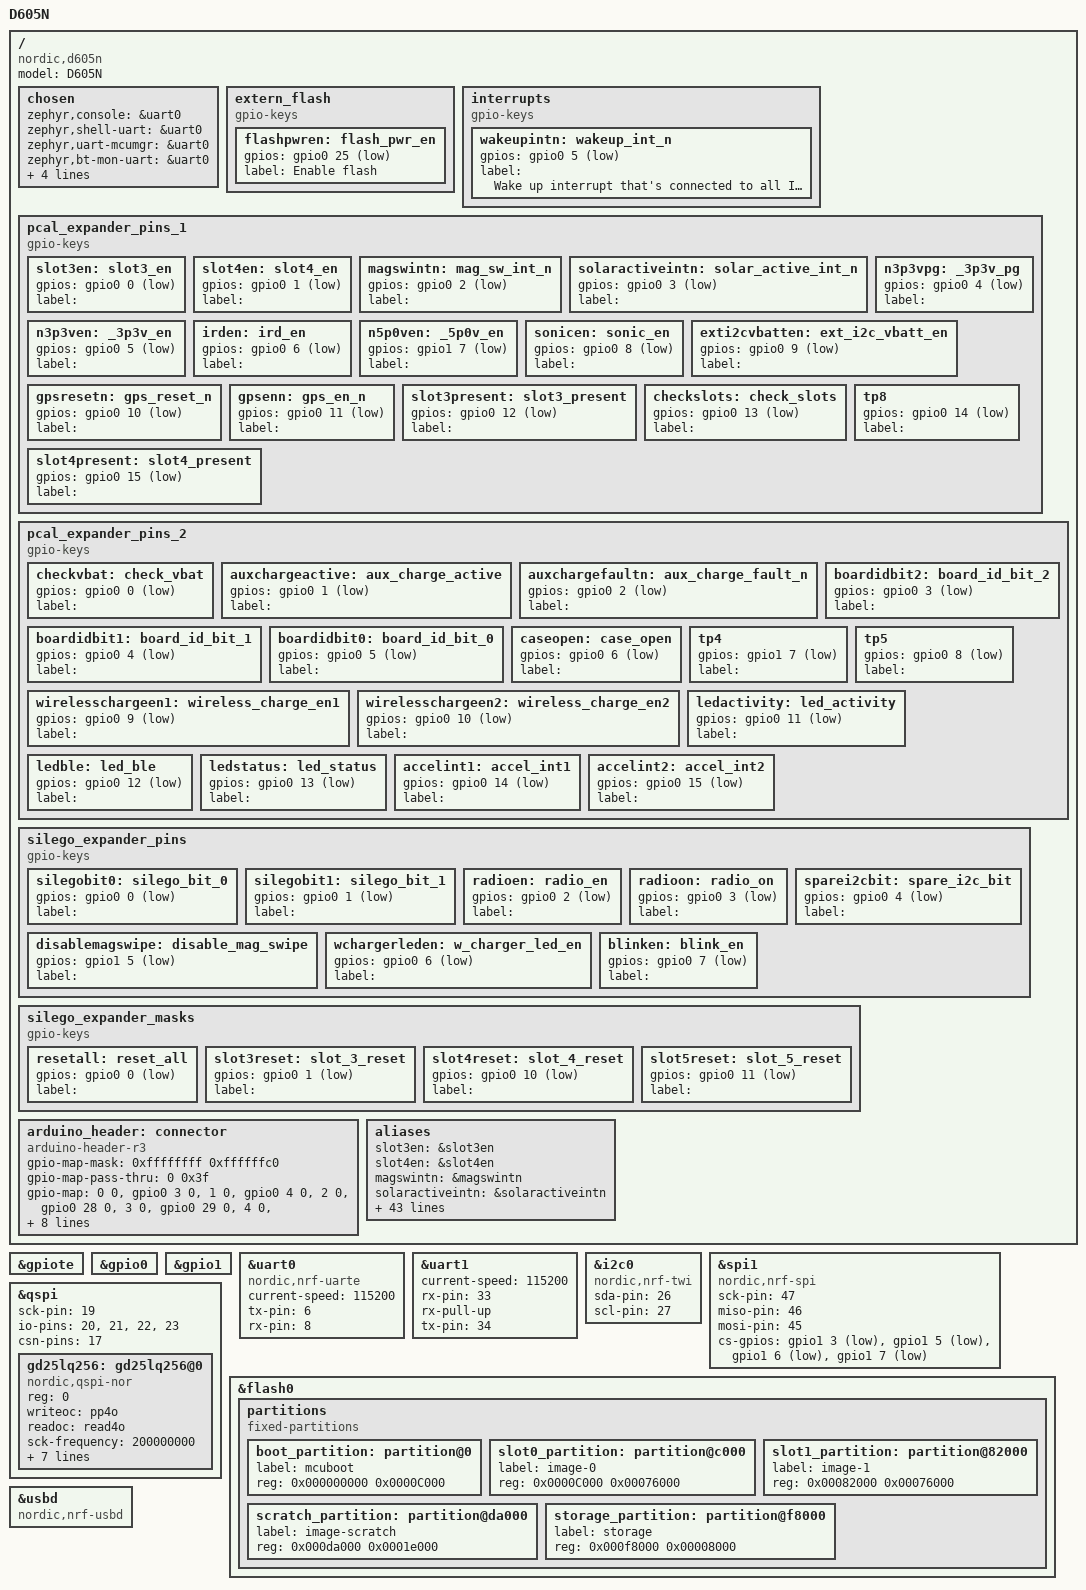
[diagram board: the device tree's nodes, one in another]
/*
 * Copyright (c) 2017 Linaro Limited
 *
 * SPDX-License-Identifier: Apache-2.0
 */

/dts-v1/;
#include <nordic/nrf52840_qiaa.dtsi>

/ {
    model = "D605N";
    compatible = "nordic,d605n";

    chosen {
        zephyr,console = &uart0;
        zephyr,shell-uart = &uart0;
        zephyr,uart-mcumgr = &uart0;
        zephyr,bt-mon-uart = &uart0;
        zephyr,bt-c2h-uart = &uart0;
        zephyr,sram = &sram0;
        zephyr,flash = &flash0;
        zephyr,code-partition = &slot0_partition;
    };

    /*extern_i2c {
        disExternI2C: dis_extern_i2c {
            gpios = <&gpio0 16 (GPIO_ACTIVE_HIGH)>;
            label = "Disable External I2C";
        };
    };*/

    extern_flash {
        compatible = "gpio-keys";

        flashpwren: flash_pwr_en {
            gpios = <&gpio0 25 (GPIO_PULL_UP | GPIO_ACTIVE_LOW)>;
            label = "Enable flash";
        };
        /* ecs: E_C_S {
            gpios = <&gpio0 24 (GPIO_ACTIVE_LOW)>;
            label = "Has something to do with flash";
        }; */
    };

    interrupts {
        compatible = "gpio-keys";

        wakeupintn: wakeup_int_n {
            gpios = <&gpio0 5 (GPIO_ACTIVE_LOW)>;
            label = "Wake up interrupt that's connected to all IO expanders";
        };
    };

    pcal_expander_pins_1 {
        compatible = "gpio-keys";

        slot3en: slot3_en {
            gpios = <&gpio0 0 (GPIO_ACTIVE_LOW)>;
            label = "";
        };

        slot4en: slot4_en {
            gpios = <&gpio0 1 (GPIO_ACTIVE_LOW)>;
            label = "";
        };

        magswintn: mag_sw_int_n {
            gpios = <&gpio0 2 (GPIO_ACTIVE_LOW)>;
            label = "";
        };

        solaractiveintn: solar_active_int_n {
            gpios = <&gpio0 3 (GPIO_ACTIVE_LOW)>;
            label = "";
        };

        n3p3vpg: _3p3v_pg {
            gpios = <&gpio0 4 (GPIO_ACTIVE_LOW)>;
            label = "";
        };

        n3p3ven: _3p3v_en {
            gpios = <&gpio0 5 (GPIO_ACTIVE_LOW)>;
            label = "";
        };

        irden: ird_en {
            gpios = <&gpio0 6 (GPIO_ACTIVE_LOW)>;
            label = "";
        };

        n5p0ven: _5p0v_en {
            gpios = <&gpio1 7 (GPIO_ACTIVE_LOW)>;
            label = "";
        };

        sonicen: sonic_en {
            gpios = <&gpio0 8 (GPIO_ACTIVE_LOW)>;
            label = "";
        };

        exti2cvbatten: ext_i2c_vbatt_en {
            gpios = <&gpio0 9 (GPIO_ACTIVE_LOW)>;
            label = "";
        };

        gpsresetn: gps_reset_n {
            gpios = <&gpio0 10 (GPIO_ACTIVE_LOW)>;
            label = "";
        };

        gpsenn: gps_en_n {
            gpios = <&gpio0 11 (GPIO_ACTIVE_LOW)>;
            label = "";
        };

        slot3present: slot3_present {
            gpios = <&gpio0 12 (GPIO_ACTIVE_LOW)>;
            label = "";
        };

        checkslots: check_slots {
            gpios = <&gpio0 13 (GPIO_ACTIVE_LOW)>;
            label = "";
        };

        tp8: tp8 {
            gpios = <&gpio0 14 (GPIO_ACTIVE_LOW)>;
            label = "";
        };

        slot4present: slot4_present {
            gpios = <&gpio0 15 (GPIO_ACTIVE_LOW)>;
            label = "";
        };
    };

    pcal_expander_pins_2 {
        compatible = "gpio-keys";

        checkvbat: check_vbat {
            gpios = <&gpio0 0 (GPIO_ACTIVE_LOW)>;
            label = "";
        };

        auxchargeactive: aux_charge_active {
            gpios = <&gpio0 1 (GPIO_ACTIVE_LOW)>;
            label = "";
        };

        auxchargefaultn: aux_charge_fault_n {
            gpios = <&gpio0 2 (GPIO_ACTIVE_LOW)>;
            label = "";
        };

        boardidbit2: board_id_bit_2 {
            gpios = <&gpio0 3 (GPIO_ACTIVE_LOW)>;
            label = "";
        };

        boardidbit1: board_id_bit_1 {
            gpios = <&gpio0 4 (GPIO_ACTIVE_LOW)>;
            label = "";
        };

        boardidbit0: board_id_bit_0 {
            gpios = <&gpio0 5 (GPIO_ACTIVE_LOW)>;
            label = "";
        };

        caseopen: case_open {
            gpios = <&gpio0 6 (GPIO_ACTIVE_LOW)>;
            label = "";
        };

        tp4: tp4 {
            gpios = <&gpio1 7 (GPIO_ACTIVE_LOW)>;
            label = "";
        };

        tp5: tp5 {
            gpios = <&gpio0 8 (GPIO_ACTIVE_LOW)>;
            label = "";
        };

        wirelesschargeen1: wireless_charge_en1 {
            gpios = <&gpio0 9 (GPIO_ACTIVE_LOW)>;
            label = "";
        };

        wirelesschargeen2: wireless_charge_en2 {
            gpios = <&gpio0 10 (GPIO_ACTIVE_LOW)>;
            label = "";
        };

        ledactivity: led_activity {
            gpios = <&gpio0 11 (GPIO_ACTIVE_LOW)>;
            label = "";
        };

        ledble: led_ble {
            gpios = <&gpio0 12 (GPIO_ACTIVE_LOW)>;
            label = "";
        };

        ledstatus: led_status {
            gpios = <&gpio0 13 (GPIO_ACTIVE_LOW)>;
            label = "";
        };

        accelint1: accel_int1 {
            gpios = <&gpio0 14 (GPIO_ACTIVE_LOW)>;
            label = "";
        };

        accelint2: accel_int2 {
            gpios = <&gpio0 15 (GPIO_ACTIVE_LOW)>;
            label = "";
        };
    };

    silego_expander_pins {
        compatible = "gpio-keys";

        silegobit0: silego_bit_0 { gpios = <&gpio0 0 (GPIO_ACTIVE_LOW)>; label = ""; };
        silegobit1: silego_bit_1 { gpios = <&gpio0 1 (GPIO_ACTIVE_LOW)>; label = ""; };
        radioen: radio_en { gpios = <&gpio0 2 (GPIO_ACTIVE_LOW)>; label = ""; };
        radioon: radio_on { gpios = <&gpio0 3 (GPIO_ACTIVE_LOW)>; label = ""; };
        
        sparei2cbit: spare_i2c_bit { gpios = <&gpio0 4 (GPIO_ACTIVE_LOW)>; label = ""; };
        disablemagswipe: disable_mag_swipe { gpios = <&gpio1 5 (GPIO_ACTIVE_LOW)>; label = ""; };
        wchargerleden: w_charger_led_en { gpios = <&gpio0 6 (GPIO_ACTIVE_LOW)>; label = ""; };
        blinken: blink_en { gpios = <&gpio0 7 (GPIO_ACTIVE_LOW)>; label = ""; };
    };

    silego_expander_masks {
        compatible = "gpio-keys";
        
        resetall: reset_all { gpios = <&gpio0 0 (GPIO_ACTIVE_LOW)>; label = ""; };
        slot3reset: slot_3_reset { gpios = <&gpio0 1 (GPIO_ACTIVE_LOW)>; label = ""; };
        slot4reset: slot_4_reset { gpios = <&gpio0 10 (GPIO_ACTIVE_LOW)>; label = ""; };
        slot5reset: slot_5_reset { gpios = <&gpio0 11 (GPIO_ACTIVE_LOW)>; label = ""; };
    };
    
    /*unused {
        spare0: spare_0 {
            gpios = <&gpio0 4 (GPIO_ACTIVE_HIGH)>;
            label = "Spare pin 0";
        };
        spare1: spare_1 {
            gpios = <&gpio0 16 (GPIO_ACTIVE_HIGH)>;
            label = "Spare pin 1";
        };
        spare2: spare_2 {
            gpios = <&gpio0 13 (GPIO_ACTIVE_HIGH)>;
            label = "Spare pin 2";
        };
        // alerts the master that the slave has data queued to send. The XBee SX 868 RFModule
        // asserts this pin as soon as data is available to send to the SPI master and it
        // remains asserteduntil the SPI master has clocked out all available data.
        spiattn1n: spi_attn1_n {
            gpios = <&gpio0 11 (GPIO_ACTIVE_LOW)>;
            label = "SPI XBEE attention pin";
        };
        progrst2: prog_rst_2 {
            gpios = <&gpio0 12 (GPIO_PULL_UP | GPIO_ACTIVE_LOW)>;
            label = "Program reset 2";
        };
    }*/

    arduino_header: connector {
        compatible = "arduino-header-r3";
        #gpio-cells = <2>;
        gpio-map-mask = <0xffffffff 0xffffffc0>;
        gpio-map-pass-thru = <0 0x3f>;
        gpio-map = <0 0 &gpio0 3 0>,	/* A0 */
            <1 0 &gpio0 4 0>,	/* A1 */
            <2 0 &gpio0 28 0>,	/* A2 */
            <3 0 &gpio0 29 0>,	/* A3 */
            <4 0 &gpio0 30 0>,	/* A4 */
            <5 0 &gpio0 31 0>,	/* A5 */
            <6 0 &gpio1 1 0>,	/* D0 */
            <7 0 &gpio1 2 0>,	/* D1 */
            <8 0 &gpio1 3 0>,	/* D2 */
            <9 0 &gpio1 4 0>,	/* D3 */
            <10 0 &gpio1 5 0>,	/* D4 */
            <11 0 &gpio1 6 0>,	/* D5 */
            <12 0 &gpio1 7 0>,	/* D6 */
            <13 0 &gpio1 8 0>,	/* D7 */
            <14 0 &gpio1 10 0>,	/* D8 */
            <15 0 &gpio1 11 0>,	/* D9 */
            <16 0 &gpio1 12 0>,	/* D10 */
            <17 0 &gpio1 13 0>,	/* D11 */
            <18 0 &gpio1 14 0>,	/* D12 */
            <19 0 &gpio1 15 0>,	/* D13 */
            <20 0 &gpio0 26 0>,	/* D14 */
            <21 0 &gpio0 27 0>;	/* D15 */
    };

    aliases {
        slot3en = &slot3en;
        slot4en = &slot4en;
        magswintn = &magswintn;
        solaractiveintn = &solaractiveintn;
        n3p3vpg = &n3p3vpg;
        n3p3ven = &n3p3ven;
        irden = &irden;
        n5p0ven = &n5p0ven;
        sonicen = &sonicen;
        exti2cvbatten = &exti2cvbatten;
        gpsresetn = &gpsresetn;
        gpsenn = &gpsenn;
        slot3present = &slot3present;
        checkslots = &checkslots;
        tp8 = &tp8;
        slot4present = &slot4present;

        checkvbat = &checkvbat;
        auxchargeactive = &auxchargeactive;
        auxchargefaultn = &auxchargefaultn;
        boardidbit2 = &boardidbit2;
        boardidbit1 = &boardidbit1;
        boardidbit0 = &boardidbit0;
        caseopen = &caseopen;
        tp4 = &tp4;
        tp5 = &tp5;
        wirelesschargeen1 = &wirelesschargeen1;
        wirelesschargeen2 = &wirelesschargeen2;
        ledactivity = &ledactivity;
        ledble = &ledble;
        ledstatus = &ledstatus;
        accelint1 = &accelint1;
        accelint2 = &accelint2;

        silegobit0 = &silegobit0;
        silegobit1 = &silegobit1;
        radioen = &radioen;
        radioon = &radioon;
        sparei2cbit = &sparei2cbit;
        disablemagswipe = &disablemagswipe;
        wchargerleden = &wchargerleden;
        blinken = &blinken;

        flashpwren = &flashpwren;
        wakeupintn = &wakeupintn;
        usbd0 = &usbd;

        resetall   = &resetall;
        slot3reset = &slot3reset;
        slot4reset = &slot4reset;
        slot5reset = &slot5reset;

        /*
        disExternI2C = &disExternI2C;
        ecs = &ecs;
        spiattn1n = &spiattn1n;
        progrst2 = &progrst2;
        */
    };
};

&slot3en { status = "okay"; };
&slot4en { status = "okay"; };
&magswintn { status = "okay"; };
&solaractiveintn { status = "okay"; };
&n3p3vpg { status = "okay"; };
&n3p3ven { status = "okay"; };
&irden { status = "okay"; };
&n5p0ven { status = "okay"; };
&sonicen { status = "okay"; };
&exti2cvbatten { status = "okay"; };
&gpsresetn { status = "okay"; };
&gpsenn { status = "okay"; };
&slot3present { status = "okay"; };
&checkslots { status = "okay"; };
&tp8 { status = "okay"; };
&slot4present { status = "okay"; };

&checkvbat { status = "okay"; };
&auxchargeactive { status = "okay"; };
&auxchargefaultn { status = "okay"; };
&boardidbit2 { status = "okay"; };
&boardidbit1 { status = "okay"; };
&boardidbit0 { status = "okay"; };
&caseopen  { status = "okay"; };
&tp4 { status = "okay"; };
&tp5 { status = "okay"; };
&wirelesschargeen1 { status = "okay"; };
&wirelesschargeen2 { status = "okay"; };
&ledactivity { status = "okay"; };
&ledble { status = "okay"; };
&ledstatus { status = "okay"; };
&accelint1 { status = "okay"; };
&accelint2 { status = "okay"; };

&silegobit0  { status = "okay"; };
&silegobit1  { status = "okay"; };
&radioen  { status = "okay"; }; 
&radioon  { status = "okay"; }; 
&sparei2cbit  { status = "okay"; };
&disablemagswipe  { status = "okay"; };
&wchargerleden  { status = "okay"; };
&blinken  { status = "okay"; }; 

&flashpwren { status = "okay"; };
&wakeupintn { status = "okay"; };

&resetall { status = "okay"; };
&slot3reset { status = "okay"; };
&slot4reset { status = "okay"; };
&slot5reset { status = "okay"; };

/*
&disExternI2C { status = "okay"; };
&ecs          { status = "okay"; };
&spiattn1n    { status = "okay"; };
&progrst2     { status = "okay"; };
*/

&gpiote {
    status = "okay";
};

&gpio0 {
    status = "okay";
};

&gpio1 {
    status = "okay";
};

&uart0 {
    compatible = "nordic,nrf-uarte";
    status = "okay";
    current-speed = <115200>;
    tx-pin = <6>;
    rx-pin = <8>;
};

&uart1 {
    status = "okay";
    current-speed = <115200>;
    rx-pin = <33>;
    rx-pull-up;
    tx-pin = <34>;
};

&i2c0 {
    compatible = "nordic,nrf-twi";
    status = "okay";
    sda-pin = <26>;
    scl-pin = <27>;
};

&spi1 {
    compatible = "nordic,nrf-spi";
    status = "okay";
    sck-pin = <47>;
    miso-pin = <46>;
    mosi-pin = <45>;
    cs-gpios = <&gpio1 3 GPIO_ACTIVE_LOW>, <&gpio1 5 GPIO_ACTIVE_LOW>, <&gpio1 6 GPIO_ACTIVE_LOW>, <&gpio1 7 GPIO_ACTIVE_LOW>;
};

&qspi {
    status = "okay";
    sck-pin = <19>;
    io-pins = <20>, <21>, <22>, <23>;
    csn-pins = <17>;
    gd25lq256: gd25lq256@0 {
        /* NOTE: Quad mode IS supported after Jake modified the zephyr driver
        */
        compatible = "nordic,qspi-nor";
        reg = <0>;
        writeoc = "pp4o";
        readoc = "read4o";
        sck-frequency = <200000000>;
        label = "GD25LQ256";
        jedec-id = [c8 66 19];
        size = <268435456>;
        address-size-32;
        has-dpd;
        t-enter-dpd = <20000>;
        t-exit-dpd = <20000>;
    };
};

&flash0 {

    partitions {
        compatible = "fixed-partitions";
        #address-cells = <1>;
        #size-cells = <1>;

        boot_partition: partition@0 {
            label = "mcuboot";
            reg = <0x000000000 0x0000C000>;
        };
        slot0_partition: partition@c000 {
            label = "image-0";
            reg = <0x0000C000 0x00076000>;
        };
        slot1_partition: partition@82000 {
            label = "image-1";
            reg = <0x00082000 0x00076000>;
        };
                /* change list:
                * 1/30/2023 - Run out of memory
                ** 1. */
        scratch_partition: partition@da000 {
            label = "image-scratch";
            reg = <0x000da000 0x0001e000>;
        };

        /*
            * The flash starting at 0x000f8000 and ending at
            * 0x000fffff is reserved for use by the application.
            */

        /*
            * Storage partition will be used by FCB/LittleFS/NVS
            * if enabled.
            */
        storage_partition: partition@f8000 {
            label = "storage";
            reg = <0x000f8000 0x00008000>;
        };
    };
};

&usbd {
    compatible = "nordic,nrf-usbd";
    status = "okay";
};
